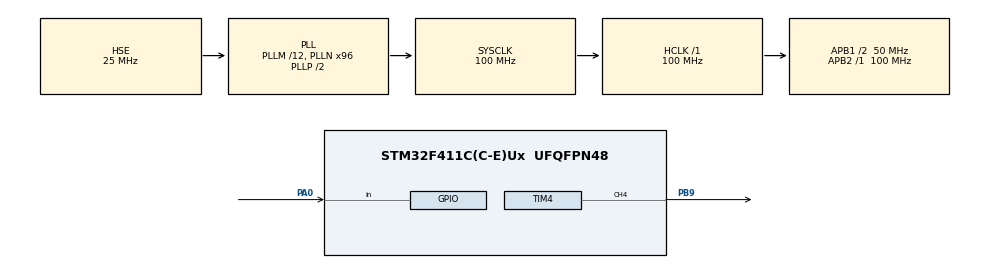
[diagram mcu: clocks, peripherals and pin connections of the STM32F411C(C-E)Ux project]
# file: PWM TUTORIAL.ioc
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Mcu.Family=STM32F4
Mcu.Name=STM32F411C(C-E)Ux
Mcu.Package=UFQFPN48
NVIC.PriorityGroup=NVIC_PRIORITYGROUP_4
PA0-WKUP.GPIO_PuPd=GPIO_PULLUP
PA0-WKUP.Signal=GPIO_Input
PB9.Signal=S_TIM4_CH4
PH0\ -\ OSC_IN.Mode=HSE-External-Oscillator
PH0\ -\ OSC_IN.Signal=RCC_OSC_IN
PH1\ -\ OSC_OUT.Mode=HSE-External-Oscillator
PH1\ -\ OSC_OUT.Signal=RCC_OSC_OUT
ProjectManager.HeapSize=0x200
ProjectManager.StackSize=0x400
ProjectManager.TargetToolchain=STM32CubeIDE
RCC.48MHZClocksFreq_Value=50000000
RCC.AHBFreq_Value=100000000
RCC.APB1CLKDivider=RCC_HCLK_DIV2
RCC.APB1Freq_Value=50000000
RCC.APB1TimFreq_Value=100000000
RCC.APB2Freq_Value=100000000
RCC.APB2TimFreq_Value=100000000
RCC.CortexFreq_Value=100000000
RCC.HCLKFreq_Value=100000000
RCC.HSE_VALUE=25000000
RCC.HSI_VALUE=16000000
RCC.LSE_VALUE=32768
RCC.PLLM=12
RCC.PLLN=96
RCC.PLLSourceVirtual=RCC_PLLSOURCE_HSE
RCC.SYSCLKFreq_VALUE=100000000
RCC.SYSCLKSource=RCC_SYSCLKSOURCE_PLLCLK
RCC.VCOOutputFreq_Value=200000000
SH.S_TIM4_CH4.0=TIM4_CH4,PWM Generation4 CH4
TIM4.Channel-PWM\ Generation4\ CH4=TIM_CHANNEL_4
TIM4.Period=19999
TIM4.Prescaler=99
board=custom

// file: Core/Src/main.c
/* USER CODE BEGIN Header */
/**
  ******************************************************************************
  * @file           : main.c
  * @brief          : Main program body
  ******************************************************************************
  * @attention
  *
  * Copyright (c) 2024 STMicroelectronics.
  * All rights reserved.
  *
  * This software is licensed under terms that can be found in the LICENSE file
  * in the root directory of this software component.
  * If no LICENSE file comes with this software, it is provided AS-IS.
  *
  ******************************************************************************
  */
/* USER CODE END Header */
#include "main.h"

TIM_HandleTypeDef htim4;

void SystemClock_Config(void);
static void MX_GPIO_Init(void);
static void MX_TIM4_Init(void);

int main(void)
{

  /* MCU Configuration--------------------------------------------------------*/

  /* Reset of all peripherals, Initializes the Flash interface and the Systick. */
  HAL_Init();

  /* Configure the system clock */
  SystemClock_Config();

  /* Initialize all configured peripherals */
  MX_GPIO_Init();
  MX_TIM4_Init();
  /* USER CODE BEGIN 2 */
  HAL_TIM_PWM_Start(&htim4, TIM_CHANNEL_4);

  uint16_t count = 499;
  uint8_t switcher = 0;

  /* USER CODE END 2 */

  /* Infinite loop */
  while (1)
  {

    /* USER CODE BEGIN 3 */
	  /*
	  if (count < 499) {
		  count = 500;
		  switcher = 0;
	  } else if (count > 1999) {
		  count = 1998;
		  switcher = 1;
	  }
	  if (switcher == 0) {
		  count++;
	  } else {
		  count--;
	  }

	  htim4.Instance->CCR4 = count;
	  HAL_Delay(1);
	*/
	  /*
	  htim4.Instance->CCR4 = 499;
	  HAL_Delay(1000);
	  htim4.Instance->CCR4 = 1999;
	  HAL_Delay(1000);
	  */
	  if (HAL_GPIO_ReadPin(GPIOA, GPIO_PIN_0) == 1) {
		  htim4.Instance->CCR4 = 499;
	  } else {
		  htim4.Instance->CCR4 = 1999;
	  }
  }
  /* USER CODE END 3 */
}

void SystemClock_Config(void)
{
  RCC_OscInitTypeDef RCC_OscInitStruct = {0};
  RCC_ClkInitTypeDef RCC_ClkInitStruct = {0};

  /** Configure the main internal regulator output voltage
  */
  __HAL_RCC_PWR_CLK_ENABLE();
  __HAL_PWR_VOLTAGESCALING_CONFIG(PWR_REGULATOR_VOLTAGE_SCALE1);

  /** Initializes the RCC Oscillators according to the specified parameters
  * in the RCC_OscInitTypeDef structure.
  */
  RCC_OscInitStruct.OscillatorType = RCC_OSCILLATORTYPE_HSE;
  RCC_OscInitStruct.HSEState = RCC_HSE_ON;
  RCC_OscInitStruct.PLL.PLLState = RCC_PLL_ON;
  RCC_OscInitStruct.PLL.PLLSource = RCC_PLLSOURCE_HSE;
  RCC_OscInitStruct.PLL.PLLM = 12;
  RCC_OscInitStruct.PLL.PLLN = 96;
  RCC_OscInitStruct.PLL.PLLP = RCC_PLLP_DIV2;
  RCC_OscInitStruct.PLL.PLLQ = 4;
  if (HAL_RCC_OscConfig(&RCC_OscInitStruct) != HAL_OK)
  {
    Error_Handler();
  }

  /** Initializes the CPU, AHB and APB buses clocks
  */
  RCC_ClkInitStruct.ClockType = RCC_CLOCKTYPE_HCLK|RCC_CLOCKTYPE_SYSCLK
                              |RCC_CLOCKTYPE_PCLK1|RCC_CLOCKTYPE_PCLK2;
  RCC_ClkInitStruct.SYSCLKSource = RCC_SYSCLKSOURCE_PLLCLK;
  RCC_ClkInitStruct.AHBCLKDivider = RCC_SYSCLK_DIV1;
  RCC_ClkInitStruct.APB1CLKDivider = RCC_HCLK_DIV2;
  RCC_ClkInitStruct.APB2CLKDivider = RCC_HCLK_DIV1;

  if (HAL_RCC_ClockConfig(&RCC_ClkInitStruct, FLASH_LATENCY_3) != HAL_OK)
  {
    Error_Handler();
  }
}

static void MX_TIM4_Init(void)
{

  TIM_MasterConfigTypeDef sMasterConfig = {0};
  TIM_OC_InitTypeDef sConfigOC = {0};

  htim4.Instance = TIM4;
  htim4.Init.Prescaler = 99;
  htim4.Init.CounterMode = TIM_COUNTERMODE_UP;
  htim4.Init.Period = 19999;
  htim4.Init.ClockDivision = TIM_CLOCKDIVISION_DIV1;
  htim4.Init.AutoReloadPreload = TIM_AUTORELOAD_PRELOAD_DISABLE;
  if (HAL_TIM_PWM_Init(&htim4) != HAL_OK)
  {
    Error_Handler();
  }
  sMasterConfig.MasterOutputTrigger = TIM_TRGO_RESET;
  sMasterConfig.MasterSlaveMode = TIM_MASTERSLAVEMODE_DISABLE;
  if (HAL_TIMEx_MasterConfigSynchronization(&htim4, &sMasterConfig) != HAL_OK)
  {
    Error_Handler();
  }
  sConfigOC.OCMode = TIM_OCMODE_PWM1;
  sConfigOC.Pulse = 0;
  sConfigOC.OCPolarity = TIM_OCPOLARITY_HIGH;
  sConfigOC.OCFastMode = TIM_OCFAST_DISABLE;
  if (HAL_TIM_PWM_ConfigChannel(&htim4, &sConfigOC, TIM_CHANNEL_4) != HAL_OK)
  {
    Error_Handler();
  }
  HAL_TIM_MspPostInit(&htim4);

}

static void MX_GPIO_Init(void)
{
  GPIO_InitTypeDef GPIO_InitStruct = {0};

  /* GPIO Ports Clock Enable */
  __HAL_RCC_GPIOH_CLK_ENABLE();
  __HAL_RCC_GPIOA_CLK_ENABLE();
  __HAL_RCC_GPIOB_CLK_ENABLE();

  /*Configure GPIO pin : PA0 */
  GPIO_InitStruct.Pin = GPIO_PIN_0;
  GPIO_InitStruct.Mode = GPIO_MODE_INPUT;
  GPIO_InitStruct.Pull = GPIO_PULLUP;
  HAL_GPIO_Init(GPIOA, &GPIO_InitStruct);

}

void Error_Handler(void)
{
  __disable_irq();
  while (1)
  {
  }
}
